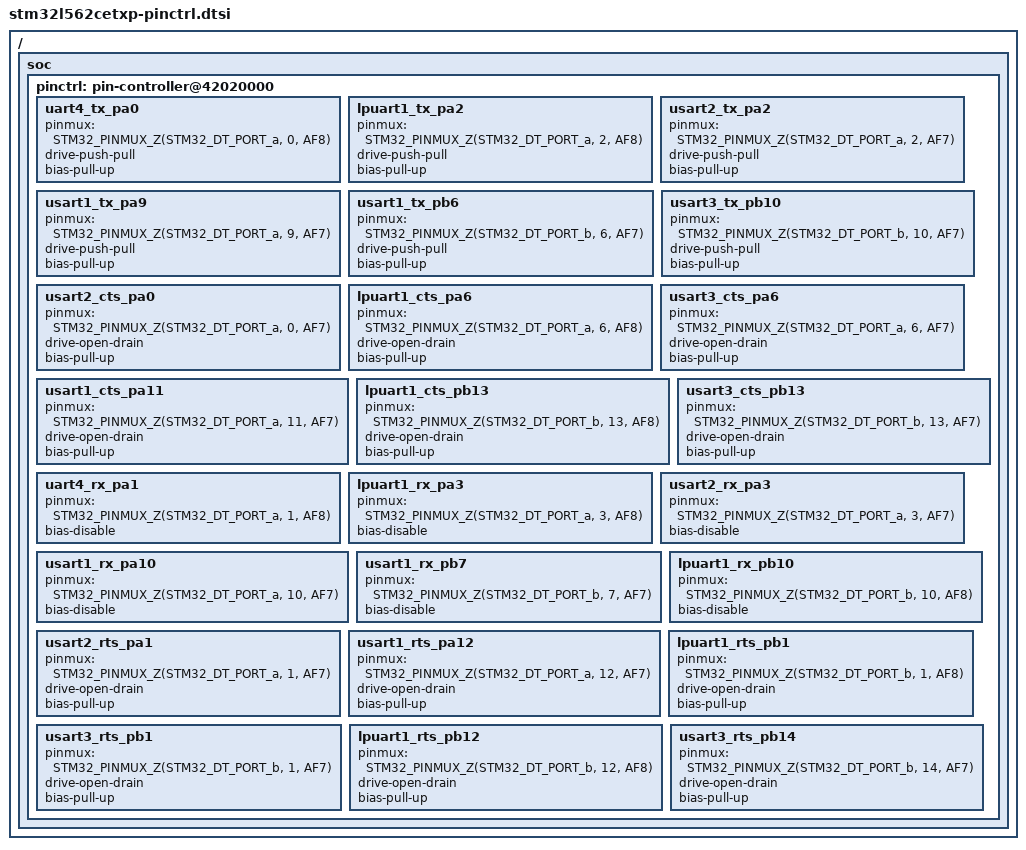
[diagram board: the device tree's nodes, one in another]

/*
 * NOTE: Autogenerated file using stm32_pinctrl_gen.py
 *
 * SPDX-License-Identifier: Apache-2.0
 */

#include <dt-bindings/pinctrl/stm32-pinctrl.h>

/ {
	soc {
		pinctrl: pin-controller@42020000 {
			/* UART_TX */
			uart4_tx_pa0: uart4_tx_pa0 {
				pinmux = <STM32_PINMUX_Z(STM32_DT_PORT_a, 0, AF8)>;
				drive-push-pull;
				bias-pull-up;
			};

			lpuart1_tx_pa2: lpuart1_tx_pa2 {
				pinmux = <STM32_PINMUX_Z(STM32_DT_PORT_a, 2, AF8)>;
				drive-push-pull;
				bias-pull-up;
			};

			lpuart1_tx_pa2: lpuart1_tx_pa2 {
				pinmux = <STM32_PINMUX_Z(STM32_DT_PORT_a, 2, AF8)>;
				drive-push-pull;
				bias-pull-up;
			};

			usart2_tx_pa2: usart2_tx_pa2 {
				pinmux = <STM32_PINMUX_Z(STM32_DT_PORT_a, 2, AF7)>;
				drive-push-pull;
				bias-pull-up;
			};

			usart1_tx_pa9: usart1_tx_pa9 {
				pinmux = <STM32_PINMUX_Z(STM32_DT_PORT_a, 9, AF7)>;
				drive-push-pull;
				bias-pull-up;
			};

			usart1_tx_pb6: usart1_tx_pb6 {
				pinmux = <STM32_PINMUX_Z(STM32_DT_PORT_b, 6, AF7)>;
				drive-push-pull;
				bias-pull-up;
			};

			usart3_tx_pb10: usart3_tx_pb10 {
				pinmux = <STM32_PINMUX_Z(STM32_DT_PORT_b, 10, AF7)>;
				drive-push-pull;
				bias-pull-up;
			};


			/* UART_CTS */
			usart2_cts_pa0: usart2_cts_pa0 {
				pinmux = <STM32_PINMUX_Z(STM32_DT_PORT_a, 0, AF7)>;
				drive-open-drain;
				bias-pull-up;
			};

			lpuart1_cts_pa6: lpuart1_cts_pa6 {
				pinmux = <STM32_PINMUX_Z(STM32_DT_PORT_a, 6, AF8)>;
				drive-open-drain;
				bias-pull-up;
			};

			lpuart1_cts_pa6: lpuart1_cts_pa6 {
				pinmux = <STM32_PINMUX_Z(STM32_DT_PORT_a, 6, AF8)>;
				drive-open-drain;
				bias-pull-up;
			};

			usart3_cts_pa6: usart3_cts_pa6 {
				pinmux = <STM32_PINMUX_Z(STM32_DT_PORT_a, 6, AF7)>;
				drive-open-drain;
				bias-pull-up;
			};

			usart1_cts_pa11: usart1_cts_pa11 {
				pinmux = <STM32_PINMUX_Z(STM32_DT_PORT_a, 11, AF7)>;
				drive-open-drain;
				bias-pull-up;
			};

			lpuart1_cts_pb13: lpuart1_cts_pb13 {
				pinmux = <STM32_PINMUX_Z(STM32_DT_PORT_b, 13, AF8)>;
				drive-open-drain;
				bias-pull-up;
			};

			lpuart1_cts_pb13: lpuart1_cts_pb13 {
				pinmux = <STM32_PINMUX_Z(STM32_DT_PORT_b, 13, AF8)>;
				drive-open-drain;
				bias-pull-up;
			};

			usart3_cts_pb13: usart3_cts_pb13 {
				pinmux = <STM32_PINMUX_Z(STM32_DT_PORT_b, 13, AF7)>;
				drive-open-drain;
				bias-pull-up;
			};


			/* UART_RX */
			uart4_rx_pa1: uart4_rx_pa1 {
				pinmux = <STM32_PINMUX_Z(STM32_DT_PORT_a, 1, AF8)>;
				bias-disable;
			};

			lpuart1_rx_pa3: lpuart1_rx_pa3 {
				pinmux = <STM32_PINMUX_Z(STM32_DT_PORT_a, 3, AF8)>;
				bias-disable;
			};

			lpuart1_rx_pa3: lpuart1_rx_pa3 {
				pinmux = <STM32_PINMUX_Z(STM32_DT_PORT_a, 3, AF8)>;
				bias-disable;
			};

			usart2_rx_pa3: usart2_rx_pa3 {
				pinmux = <STM32_PINMUX_Z(STM32_DT_PORT_a, 3, AF7)>;
				bias-disable;
			};

			usart1_rx_pa10: usart1_rx_pa10 {
				pinmux = <STM32_PINMUX_Z(STM32_DT_PORT_a, 10, AF7)>;
				bias-disable;
			};

			usart1_rx_pb7: usart1_rx_pb7 {
				pinmux = <STM32_PINMUX_Z(STM32_DT_PORT_b, 7, AF7)>;
				bias-disable;
			};

			lpuart1_rx_pb10: lpuart1_rx_pb10 {
				pinmux = <STM32_PINMUX_Z(STM32_DT_PORT_b, 10, AF8)>;
				bias-disable;
			};

			lpuart1_rx_pb10: lpuart1_rx_pb10 {
				pinmux = <STM32_PINMUX_Z(STM32_DT_PORT_b, 10, AF8)>;
				bias-disable;
			};


			/* UART_RTS */
			usart2_rts_pa1: usart2_rts_pa1 {
				pinmux = <STM32_PINMUX_Z(STM32_DT_PORT_a, 1, AF7)>;
				drive-open-drain;
				bias-pull-up;
			};

			usart1_rts_pa12: usart1_rts_pa12 {
				pinmux = <STM32_PINMUX_Z(STM32_DT_PORT_a, 12, AF7)>;
				drive-open-drain;
				bias-pull-up;
			};

			lpuart1_rts_pb1: lpuart1_rts_pb1 {
				pinmux = <STM32_PINMUX_Z(STM32_DT_PORT_b, 1, AF8)>;
				drive-open-drain;
				bias-pull-up;
			};

			lpuart1_rts_pb1: lpuart1_rts_pb1 {
				pinmux = <STM32_PINMUX_Z(STM32_DT_PORT_b, 1, AF8)>;
				drive-open-drain;
				bias-pull-up;
			};

			usart3_rts_pb1: usart3_rts_pb1 {
				pinmux = <STM32_PINMUX_Z(STM32_DT_PORT_b, 1, AF7)>;
				drive-open-drain;
				bias-pull-up;
			};

			lpuart1_rts_pb12: lpuart1_rts_pb12 {
				pinmux = <STM32_PINMUX_Z(STM32_DT_PORT_b, 12, AF8)>;
				drive-open-drain;
				bias-pull-up;
			};

			lpuart1_rts_pb12: lpuart1_rts_pb12 {
				pinmux = <STM32_PINMUX_Z(STM32_DT_PORT_b, 12, AF8)>;
				drive-open-drain;
				bias-pull-up;
			};

			usart3_rts_pb14: usart3_rts_pb14 {
				pinmux = <STM32_PINMUX_Z(STM32_DT_PORT_b, 14, AF7)>;
				drive-open-drain;
				bias-pull-up;
			};

		};
	};
};
